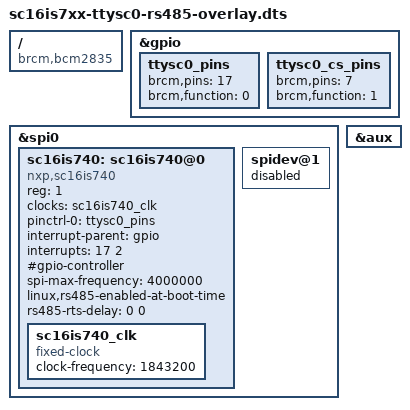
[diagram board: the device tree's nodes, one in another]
/dts-v1/;
/plugin/;

/ {
	compatible = "brcm,bcm2835", "brcm,bcm2708", "brcm,bcm2709";

	fragment@0 {
		target = <&gpio>;
		__overlay__ {
    
			ttysc0_pins: ttysc0_pins {
        			brcm,pins = <17>;
        			brcm,function = <0>; /* input */
      			};
      
      			ttysc0_cs_pins: ttysc0_cs_pins {
				brcm,pins = <7>;
				brcm,function = <1>; /* output */
      			};

		};
	};

	fragment@1 {
		target = <&spi0>;
		frag1: __overlay__ {
			#address-cells = <1>;
			#size-cells = <0>;
			
			//pinctrl-0 = <&ttysc0_pins &ttysc0_cs_pins>;			
			//cs-gpios = <&gpio 7 1>;			

			sc16is740: sc16is740@0 {
				compatible = "nxp,sc16is740";
				reg = <1>; /* CE1 */
				clocks = <&sc16is740_clk>;
				pinctrl-names = "default";
				pinctrl-0 = <&ttysc0_pins>;
				interrupt-parent = <&gpio>;
				interrupts = <17 2>; /* IRQ_TYPE_EDGE_FALLING */				
				#gpio-controller;
				#gpio-cells = <2>;
				spi-max-frequency = <4000000>;
				status = "okay";
				linux,rs485-enabled-at-boot-time;
				rs485-rts-delay = <0 0>;

				sc16is740_clk: sc16is740_clk {
					compatible = "fixed-clock";
					#clock-cells = <0>;
					clock-frequency = <1843200>;
				};
			};
		};
	};

	fragment@2 {
		target = <&aux>;
		__overlay__ {
			status = "okay";
		};
	};
	
	fragment@3 {
        	target = <&spi0>;
        	__overlay__ {
            		status = "okay";
            		spidev@1{
                		status = "disabled";
            		};
        	};
	};
	

    __overrides__ {
      int_pin = <&sc16is740>,"interrupts:0";
    };
};
